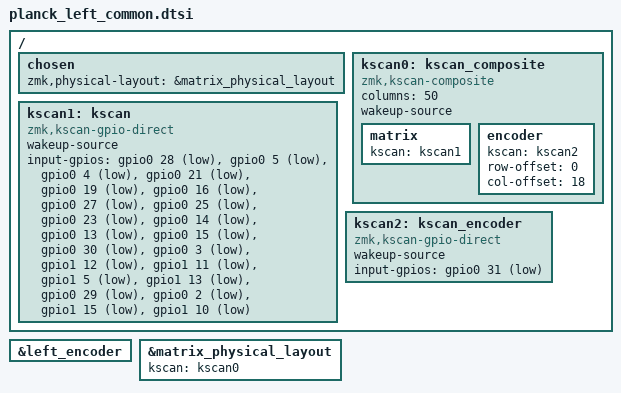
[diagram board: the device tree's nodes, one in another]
#include "planck.dtsi"
#include <dt-bindings/led/led.h>

&left_encoder {
    status = "okay";
};

&matrix_physical_layout {
    kscan = <&kscan0>;
};

/ {
    chosen {
        zmk,physical-layout = &matrix_physical_layout;
    };

    kscan0: kscan_composite {
        compatible = "zmk,kscan-composite";
        columns = <50>;
        wakeup-source;

        matrix {
            kscan = <&kscan1>;
        };

        encoder {
            kscan = <&kscan2>;
            row-offset = <0>;
            col-offset = <18>;
        };
    };

    kscan1: kscan {
        compatible = "zmk,kscan-gpio-direct";
        wakeup-source;
        input-gpios
            = <&gpio0 28 (GPIO_ACTIVE_LOW | GPIO_PULL_UP)>
            , <&gpio0 5 (GPIO_ACTIVE_LOW | GPIO_PULL_UP)>
            , <&gpio0 4 (GPIO_ACTIVE_LOW | GPIO_PULL_UP)>
            , <&gpio0 21 (GPIO_ACTIVE_LOW | GPIO_PULL_UP)>
            , <&gpio0 19 (GPIO_ACTIVE_LOW | GPIO_PULL_UP)>
            , <&gpio0 16 (GPIO_ACTIVE_LOW | GPIO_PULL_UP)>
            , <&gpio0 27 (GPIO_ACTIVE_LOW | GPIO_PULL_UP)>
            , <&gpio0 25 (GPIO_ACTIVE_LOW | GPIO_PULL_UP)>
            , <&gpio0 23 (GPIO_ACTIVE_LOW | GPIO_PULL_UP)>
            , <&gpio0 14 (GPIO_ACTIVE_LOW | GPIO_PULL_UP)>
            , <&gpio0 13 (GPIO_ACTIVE_LOW | GPIO_PULL_UP)>
            , <&gpio0 15 (GPIO_ACTIVE_LOW | GPIO_PULL_UP)>
            , <&gpio0 30 (GPIO_ACTIVE_LOW | GPIO_PULL_UP)>
            , <&gpio0 3 (GPIO_ACTIVE_LOW | GPIO_PULL_UP)>
            , <&gpio1 12 (GPIO_ACTIVE_LOW | GPIO_PULL_UP)>
            , <&gpio1 11 (GPIO_ACTIVE_LOW | GPIO_PULL_UP)>
            , <&gpio1 5 (GPIO_ACTIVE_LOW | GPIO_PULL_UP)>
            , <&gpio1 13 (GPIO_ACTIVE_LOW | GPIO_PULL_UP)>
            , <&gpio0 29 (GPIO_ACTIVE_LOW | GPIO_PULL_UP)>
            , <&gpio0 2 (GPIO_ACTIVE_LOW | GPIO_PULL_UP)>
            , <&gpio1 15 (GPIO_ACTIVE_LOW | GPIO_PULL_UP)>
            , <&gpio1 10 (GPIO_ACTIVE_LOW | GPIO_PULL_UP)>
            ;
    };

    kscan2: kscan_encoder {
        compatible = "zmk,kscan-gpio-direct";
        wakeup-source;
        input-gpios = <&gpio0 31 (GPIO_ACTIVE_LOW | GPIO_PULL_UP)>;
    };
};
